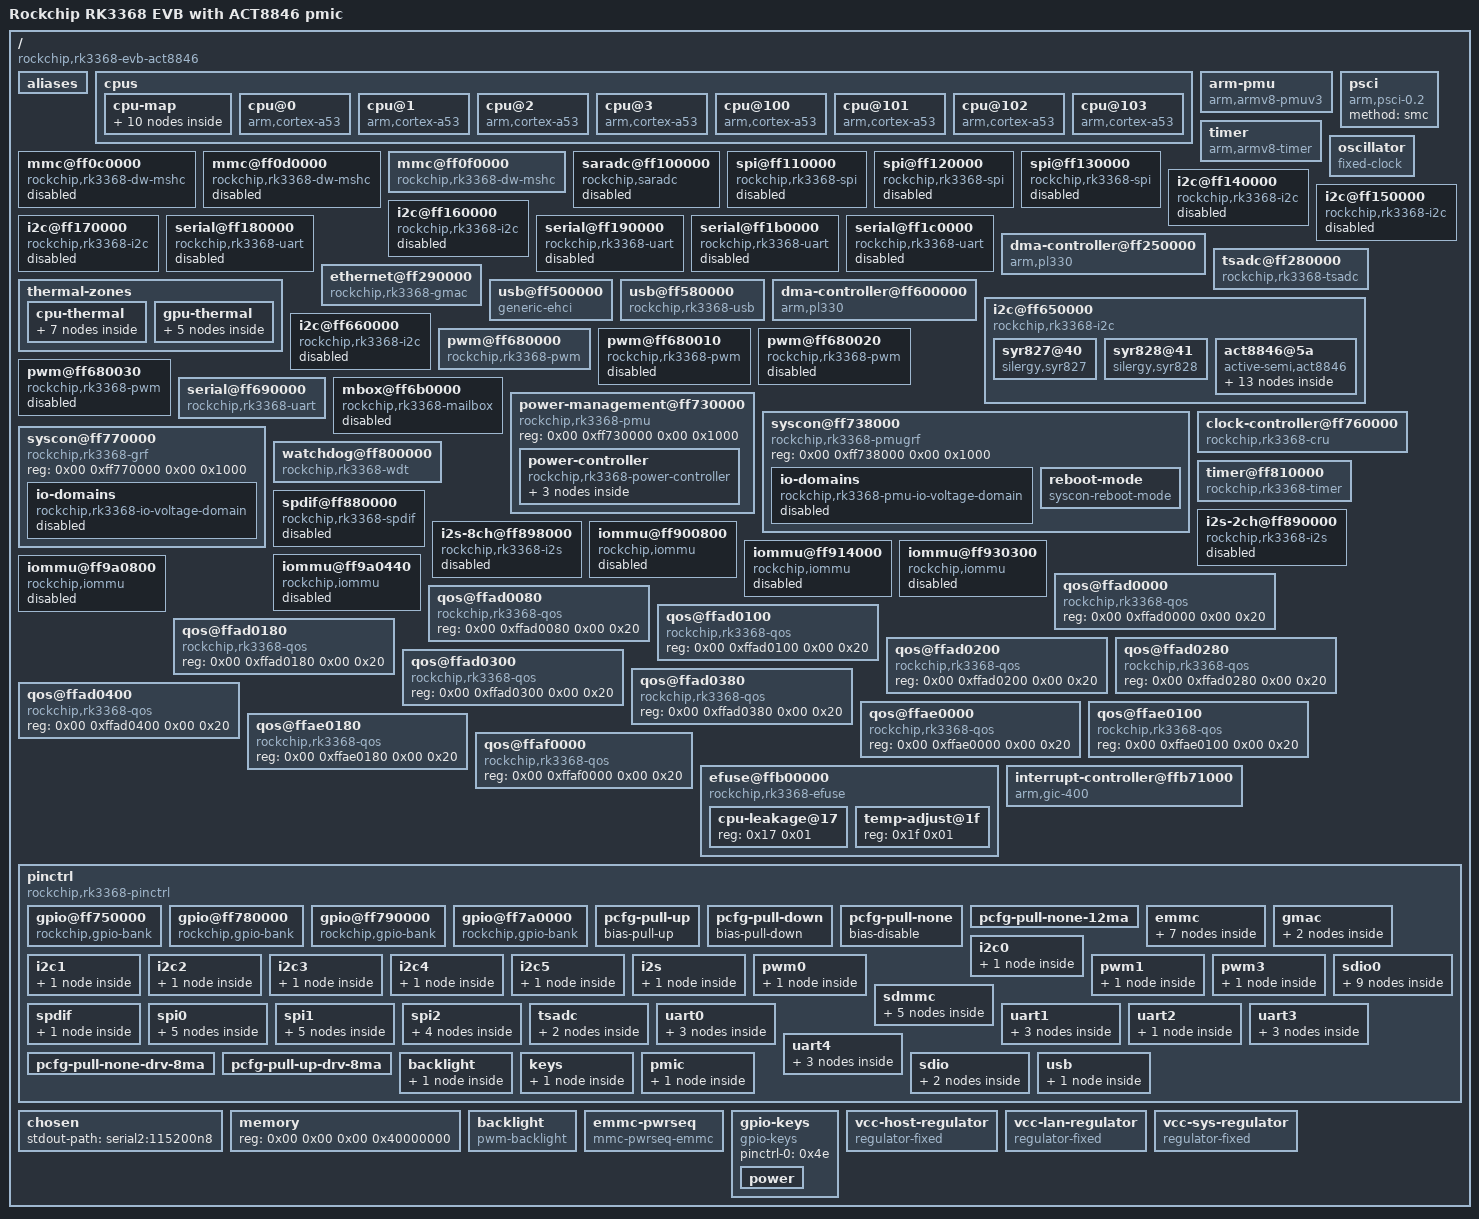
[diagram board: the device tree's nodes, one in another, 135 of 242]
/dts-v1/;

/ {
	compatible = "rockchip,rk3368-evb-act8846\0rockchip,rk3368";
	interrupt-parent = <0x01>;
	#address-cells = <0x02>;
	#size-cells = <0x02>;
	model = "Rockchip RK3368 EVB with ACT8846 pmic";

	aliases {
		ethernet0 = "/ethernet@ff290000";
		i2c0 = "/i2c@ff650000";
		i2c1 = "/i2c@ff660000";
		i2c2 = "/i2c@ff140000";
		i2c3 = "/i2c@ff150000";
		i2c4 = "/i2c@ff160000";
		i2c5 = "/i2c@ff170000";
		serial0 = "/serial@ff180000";
		serial1 = "/serial@ff190000";
		serial2 = "/serial@ff690000";
		serial3 = "/serial@ff1b0000";
		serial4 = "/serial@ff1c0000";
		spi0 = "/spi@ff110000";
		spi1 = "/spi@ff120000";
		spi2 = "/spi@ff130000";
		mmc0 = "/mmc@ff0f0000";
	};

	cpus {
		#address-cells = <0x02>;
		#size-cells = <0x00>;

		cpu-map {

			cluster0 {

				core0 {
					cpu = <0x02>;
				};

				core1 {
					cpu = <0x03>;
				};

				core2 {
					cpu = <0x04>;
				};

				core3 {
					cpu = <0x05>;
				};
			};

			cluster1 {

				core0 {
					cpu = <0x06>;
				};

				core1 {
					cpu = <0x07>;
				};

				core2 {
					cpu = <0x08>;
				};

				core3 {
					cpu = <0x09>;
				};
			};
		};

		cpu@0 {
			device_type = "cpu";
			compatible = "arm,cortex-a53";
			reg = <0x00 0x00>;
			enable-method = "psci";
			#cooling-cells = <0x02>;
			phandle = <0x06>;
		};

		cpu@1 {
			device_type = "cpu";
			compatible = "arm,cortex-a53";
			reg = <0x00 0x01>;
			enable-method = "psci";
			#cooling-cells = <0x02>;
			phandle = <0x07>;
		};

		cpu@2 {
			device_type = "cpu";
			compatible = "arm,cortex-a53";
			reg = <0x00 0x02>;
			enable-method = "psci";
			#cooling-cells = <0x02>;
			phandle = <0x08>;
		};

		cpu@3 {
			device_type = "cpu";
			compatible = "arm,cortex-a53";
			reg = <0x00 0x03>;
			enable-method = "psci";
			#cooling-cells = <0x02>;
			phandle = <0x09>;
		};

		cpu@100 {
			device_type = "cpu";
			compatible = "arm,cortex-a53";
			reg = <0x00 0x100>;
			enable-method = "psci";
			#cooling-cells = <0x02>;
			phandle = <0x02>;
		};

		cpu@101 {
			device_type = "cpu";
			compatible = "arm,cortex-a53";
			reg = <0x00 0x101>;
			enable-method = "psci";
			#cooling-cells = <0x02>;
			phandle = <0x03>;
		};

		cpu@102 {
			device_type = "cpu";
			compatible = "arm,cortex-a53";
			reg = <0x00 0x102>;
			enable-method = "psci";
			#cooling-cells = <0x02>;
			phandle = <0x04>;
		};

		cpu@103 {
			device_type = "cpu";
			compatible = "arm,cortex-a53";
			reg = <0x00 0x103>;
			enable-method = "psci";
			#cooling-cells = <0x02>;
			phandle = <0x05>;
		};
	};

	arm-pmu {
		compatible = "arm,armv8-pmuv3";
		interrupts = <0x00 0x70 0x04 0x00 0x71 0x04 0x00 0x72 0x04 0x00 0x73 0x04 0x00 0x74 0x04 0x00 0x75 0x04 0x00 0x76 0x04 0x00 0x77 0x04>;
		interrupt-affinity = <0x06 0x07 0x08 0x09 0x02 0x03 0x04 0x05>;
	};

	psci {
		compatible = "arm,psci-0.2";
		method = "smc";
	};

	timer {
		compatible = "arm,armv8-timer";
		interrupts = <0x01 0x0d 0xff04 0x01 0x0e 0xff04 0x01 0x0b 0xff04 0x01 0x0a 0xff04>;
	};

	oscillator {
		compatible = "fixed-clock";
		clock-frequency = <0x16e3600>;
		clock-output-names = "xin24m";
		#clock-cells = <0x00>;
		phandle = <0x50>;
	};

	mmc@ff0c0000 {
		compatible = "rockchip,rk3368-dw-mshc\0rockchip,rk3288-dw-mshc";
		reg = <0x00 0xff0c0000 0x00 0x4000>;
		max-frequency = <0x8f0d180>;
		clocks = <0x0a 0x1c8 0x0a 0x44 0x0a 0x72 0x0a 0x76>;
		clock-names = "biu\0ciu\0ciu-drive\0ciu-sample";
		fifo-depth = <0x100>;
		interrupts = <0x00 0x20 0x04>;
		resets = <0x0a 0x80>;
		reset-names = "reset";
		status = "disabled";
		phandle = <0x51>;
	};

	mmc@ff0d0000 {
		compatible = "rockchip,rk3368-dw-mshc\0rockchip,rk3288-dw-mshc";
		reg = <0x00 0xff0d0000 0x00 0x4000>;
		max-frequency = <0x8f0d180>;
		clocks = <0x0a 0x1c9 0x0a 0x45 0x0a 0x73 0x0a 0x77>;
		clock-names = "biu\0ciu\0ciu-drive\0ciu-sample";
		fifo-depth = <0x100>;
		interrupts = <0x00 0x21 0x04>;
		resets = <0x0a 0x81>;
		reset-names = "reset";
		status = "disabled";
		phandle = <0x52>;
	};

	mmc@ff0f0000 {
		compatible = "rockchip,rk3368-dw-mshc\0rockchip,rk3288-dw-mshc";
		reg = <0x00 0xff0f0000 0x00 0x4000>;
		max-frequency = <0x8f0d180>;
		clocks = <0x0a 0x1cb 0x0a 0x47 0x0a 0x75 0x0a 0x79>;
		clock-names = "biu\0ciu\0ciu-drive\0ciu-sample";
		fifo-depth = <0x100>;
		interrupts = <0x00 0x23 0x04>;
		resets = <0x0a 0x83>;
		reset-names = "reset";
		status = "okay";
		bus-width = <0x08>;
		cap-mmc-highspeed;
		mmc-pwrseq = <0x0b>;
		non-removable;
		pinctrl-names = "default";
		pinctrl-0 = <0x0c 0x0d 0x0e>;
		phandle = <0x53>;
	};

	saradc@ff100000 {
		compatible = "rockchip,saradc";
		reg = <0x00 0xff100000 0x00 0x100>;
		interrupts = <0x00 0x24 0x04>;
		#io-channel-cells = <0x01>;
		clocks = <0x0a 0x49 0x0a 0x15b>;
		clock-names = "saradc\0apb_pclk";
		resets = <0x0a 0x57>;
		reset-names = "saradc-apb";
		status = "disabled";
		phandle = <0x54>;
	};

	spi@ff110000 {
		compatible = "rockchip,rk3368-spi\0rockchip,rk3066-spi";
		reg = <0x00 0xff110000 0x00 0x1000>;
		clocks = <0x0a 0x41 0x0a 0x152>;
		clock-names = "spiclk\0apb_pclk";
		interrupts = <0x00 0x2c 0x04>;
		pinctrl-names = "default";
		pinctrl-0 = <0x0f 0x10 0x11 0x12>;
		#address-cells = <0x01>;
		#size-cells = <0x00>;
		status = "disabled";
		phandle = <0x55>;
	};

	spi@ff120000 {
		compatible = "rockchip,rk3368-spi\0rockchip,rk3066-spi";
		reg = <0x00 0xff120000 0x00 0x1000>;
		clocks = <0x0a 0x42 0x0a 0x153>;
		clock-names = "spiclk\0apb_pclk";
		interrupts = <0x00 0x2d 0x04>;
		pinctrl-names = "default";
		pinctrl-0 = <0x13 0x14 0x15 0x16>;
		#address-cells = <0x01>;
		#size-cells = <0x00>;
		status = "disabled";
		phandle = <0x56>;
	};

	spi@ff130000 {
		compatible = "rockchip,rk3368-spi\0rockchip,rk3066-spi";
		reg = <0x00 0xff130000 0x00 0x1000>;
		clocks = <0x0a 0x43 0x0a 0x154>;
		clock-names = "spiclk\0apb_pclk";
		interrupts = <0x00 0x29 0x04>;
		pinctrl-names = "default";
		pinctrl-0 = <0x17 0x18 0x19 0x1a>;
		#address-cells = <0x01>;
		#size-cells = <0x00>;
		status = "disabled";
		phandle = <0x57>;
	};

	i2c@ff140000 {
		compatible = "rockchip,rk3368-i2c\0rockchip,rk3288-i2c";
		reg = <0x00 0xff140000 0x00 0x1000>;
		interrupts = <0x00 0x3e 0x04>;
		#address-cells = <0x01>;
		#size-cells = <0x00>;
		clock-names = "i2c";
		clocks = <0x0a 0x14e>;
		pinctrl-names = "default";
		pinctrl-0 = <0x1b>;
		status = "disabled";
		phandle = <0x58>;
	};

	i2c@ff150000 {
		compatible = "rockchip,rk3368-i2c\0rockchip,rk3288-i2c";
		reg = <0x00 0xff150000 0x00 0x1000>;
		interrupts = <0x00 0x3f 0x04>;
		#address-cells = <0x01>;
		#size-cells = <0x00>;
		clock-names = "i2c";
		clocks = <0x0a 0x14f>;
		pinctrl-names = "default";
		pinctrl-0 = <0x1c>;
		status = "disabled";
		phandle = <0x59>;
	};

	i2c@ff160000 {
		compatible = "rockchip,rk3368-i2c\0rockchip,rk3288-i2c";
		reg = <0x00 0xff160000 0x00 0x1000>;
		interrupts = <0x00 0x40 0x04>;
		#address-cells = <0x01>;
		#size-cells = <0x00>;
		clock-names = "i2c";
		clocks = <0x0a 0x150>;
		pinctrl-names = "default";
		pinctrl-0 = <0x1d>;
		status = "disabled";
		phandle = <0x5a>;
	};

	i2c@ff170000 {
		compatible = "rockchip,rk3368-i2c\0rockchip,rk3288-i2c";
		reg = <0x00 0xff170000 0x00 0x1000>;
		interrupts = <0x00 0x41 0x04>;
		#address-cells = <0x01>;
		#size-cells = <0x00>;
		clock-names = "i2c";
		clocks = <0x0a 0x151>;
		pinctrl-names = "default";
		pinctrl-0 = <0x1e>;
		status = "disabled";
		phandle = <0x5b>;
	};

	serial@ff180000 {
		compatible = "rockchip,rk3368-uart\0snps,dw-apb-uart";
		reg = <0x00 0xff180000 0x00 0x100>;
		clock-frequency = <0x16e3600>;
		clocks = <0x0a 0x4d 0x0a 0x155>;
		clock-names = "baudclk\0apb_pclk";
		interrupts = <0x00 0x37 0x04>;
		reg-shift = <0x02>;
		reg-io-width = <0x04>;
		status = "disabled";
		phandle = <0x5c>;
	};

	serial@ff190000 {
		compatible = "rockchip,rk3368-uart\0snps,dw-apb-uart";
		reg = <0x00 0xff190000 0x00 0x100>;
		clock-frequency = <0x16e3600>;
		clocks = <0x0a 0x4e 0x0a 0x156>;
		clock-names = "baudclk\0apb_pclk";
		interrupts = <0x00 0x38 0x04>;
		reg-shift = <0x02>;
		reg-io-width = <0x04>;
		status = "disabled";
		phandle = <0x5d>;
	};

	serial@ff1b0000 {
		compatible = "rockchip,rk3368-uart\0snps,dw-apb-uart";
		reg = <0x00 0xff1b0000 0x00 0x100>;
		clock-frequency = <0x16e3600>;
		clocks = <0x0a 0x50 0x0a 0x158>;
		clock-names = "baudclk\0apb_pclk";
		interrupts = <0x00 0x3a 0x04>;
		reg-shift = <0x02>;
		reg-io-width = <0x04>;
		status = "disabled";
		phandle = <0x5e>;
	};

	serial@ff1c0000 {
		compatible = "rockchip,rk3368-uart\0snps,dw-apb-uart";
		reg = <0x00 0xff1c0000 0x00 0x100>;
		clock-frequency = <0x16e3600>;
		clocks = <0x0a 0x51 0x0a 0x159>;
		clock-names = "baudclk\0apb_pclk";
		interrupts = <0x00 0x3b 0x04>;
		reg-shift = <0x02>;
		reg-io-width = <0x04>;
		status = "disabled";
		phandle = <0x5f>;
	};

	dma-controller@ff250000 {
		compatible = "arm,pl330\0arm,primecell";
		reg = <0x00 0xff250000 0x00 0x4000>;
		interrupts = <0x00 0x02 0x04 0x00 0x03 0x04>;
		#dma-cells = <0x01>;
		arm,pl330-broken-no-flushp;
		arm,pl330-periph-burst;
		clocks = <0x0a 0xc3>;
		clock-names = "apb_pclk";
		phandle = <0x60>;
	};

	thermal-zones {

		cpu-thermal {
			polling-delay-passive = <0x64>;
			polling-delay = <0x1388>;
			thermal-sensors = <0x1f 0x00>;
			phandle = <0x61>;

			trips {

				cpu_alert0 {
					temperature = <0x124f8>;
					hysteresis = <0x7d0>;
					type = "passive";
					phandle = <0x20>;
				};

				cpu_alert1 {
					temperature = <0x13880>;
					hysteresis = <0x7d0>;
					type = "passive";
					phandle = <0x21>;
				};

				cpu_crit {
					temperature = <0x17318>;
					hysteresis = <0x7d0>;
					type = "critical";
					phandle = <0x62>;
				};
			};

			cooling-maps {

				map0 {
					trip = <0x20>;
					cooling-device = <0x02 0xffffffff 0xffffffff 0x03 0xffffffff 0xffffffff 0x04 0xffffffff 0xffffffff 0x05 0xffffffff 0xffffffff>;
				};

				map1 {
					trip = <0x21>;
					cooling-device = <0x06 0xffffffff 0xffffffff 0x07 0xffffffff 0xffffffff 0x08 0xffffffff 0xffffffff 0x09 0xffffffff 0xffffffff>;
				};
			};
		};

		gpu-thermal {
			polling-delay-passive = <0x64>;
			polling-delay = <0x1388>;
			thermal-sensors = <0x1f 0x01>;
			phandle = <0x63>;

			trips {

				gpu_alert0 {
					temperature = <0x13880>;
					hysteresis = <0x7d0>;
					type = "passive";
					phandle = <0x22>;
				};

				gpu_crit {
					temperature = <0x1c138>;
					hysteresis = <0x7d0>;
					type = "critical";
					phandle = <0x64>;
				};
			};

			cooling-maps {

				map0 {
					trip = <0x22>;
					cooling-device = <0x02 0xffffffff 0xffffffff 0x03 0xffffffff 0xffffffff 0x04 0xffffffff 0xffffffff 0x05 0xffffffff 0xffffffff>;
				};
			};
		};
	};

	tsadc@ff280000 {
		compatible = "rockchip,rk3368-tsadc";
		reg = <0x00 0xff280000 0x00 0x100>;
		interrupts = <0x00 0x25 0x04>;
		clocks = <0x0a 0x48 0x0a 0x15a>;
		clock-names = "tsadc\0apb_pclk";
		resets = <0x0a 0x9f>;
		reset-names = "tsadc-apb";
		pinctrl-names = "init\0default\0sleep";
		pinctrl-0 = <0x23>;
		pinctrl-1 = <0x24>;
		pinctrl-2 = <0x23>;
		#thermal-sensor-cells = <0x01>;
		rockchip,hw-tshut-temp = <0x17318>;
		status = "okay";
		rockchip,hw-tshut-mode = <0x00>;
		rockchip,hw-tshut-polarity = <0x00>;
		phandle = <0x1f>;
	};

	ethernet@ff290000 {
		compatible = "rockchip,rk3368-gmac";
		reg = <0x00 0xff290000 0x00 0x10000>;
		interrupts = <0x00 0x1b 0x04>;
		interrupt-names = "macirq";
		rockchip,grf = <0x25>;
		clocks = <0x0a 0x7f 0x0a 0x66 0x0a 0x67 0x0a 0x63 0x0a 0x80 0x0a 0xc5 0x0a 0x15d>;
		clock-names = "stmmaceth\0mac_clk_rx\0mac_clk_tx\0clk_mac_ref\0clk_mac_refout\0aclk_mac\0pclk_mac";
		status = "okay";
		phy-supply = <0x26>;
		phy-mode = "rmii";
		clock_in_out = "output";
		snps,reset-gpio = <0x27 0x0c 0x00>;
		snps,reset-active-low;
		snps,reset-delays-us = <0x00 0x2710 0xf4240>;
		pinctrl-names = "default";
		pinctrl-0 = <0x28>;
		tx_delay = <0x30>;
		rx_delay = <0x10>;
		phandle = <0x65>;
	};

	usb@ff500000 {
		compatible = "generic-ehci";
		reg = <0x00 0xff500000 0x00 0x100>;
		interrupts = <0x00 0x18 0x04>;
		clocks = <0x0a 0x1c2>;
		status = "okay";
		phandle = <0x66>;
	};

	usb@ff580000 {
		compatible = "rockchip,rk3368-usb\0rockchip,rk3066-usb\0snps,dwc2";
		reg = <0x00 0xff580000 0x00 0x40000>;
		interrupts = <0x00 0x17 0x04>;
		clocks = <0x0a 0x1c1>;
		clock-names = "otg";
		dr_mode = "host";
		g-np-tx-fifo-size = <0x10>;
		g-rx-fifo-size = <0x113>;
		g-tx-fifo-size = <0x100 0x80 0x80 0x40 0x40 0x20>;
		status = "okay";
		phandle = <0x67>;
	};

	dma-controller@ff600000 {
		compatible = "arm,pl330\0arm,primecell";
		reg = <0x00 0xff600000 0x00 0x4000>;
		interrupts = <0x00 0x00 0x04 0x00 0x01 0x04>;
		#dma-cells = <0x01>;
		arm,pl330-broken-no-flushp;
		arm,pl330-periph-burst;
		clocks = <0x0a 0xc2>;
		clock-names = "apb_pclk";
		phandle = <0x3f>;
	};

	i2c@ff650000 {
		compatible = "rockchip,rk3368-i2c\0rockchip,rk3288-i2c";
		reg = <0x00 0xff650000 0x00 0x1000>;
		clocks = <0x0a 0x14c>;
		clock-names = "i2c";
		interrupts = <0x00 0x3c 0x04>;
		pinctrl-names = "default";
		pinctrl-0 = <0x29>;
		#address-cells = <0x01>;
		#size-cells = <0x00>;
		status = "okay";
		clock-frequency = <0x61a80>;
		phandle = <0x68>;

		syr827@40 {
			compatible = "silergy,syr827";
			reg = <0x40>;
			fcs,suspend-voltage-selector = <0x01>;
			regulator-name = "vdd_cpu";
			regulator-min-microvolt = <0xcf850>;
			regulator-max-microvolt = <0x149970>;
			regulator-always-on;
			regulator-boot-on;
			vin-supply = <0x2a>;
			phandle = <0x69>;
		};

		syr828@41 {
			compatible = "silergy,syr828";
			reg = <0x41>;
			fcs,suspend-voltage-selector = <0x01>;
			regulator-name = "vdd_gpu";
			regulator-min-microvolt = <0xcf850>;
			regulator-max-microvolt = <0x149970>;
			regulator-always-on;
			vin-supply = <0x2a>;
			phandle = <0x6a>;
		};

		act8846@5a {
			compatible = "active-semi,act8846";
			reg = <0x5a>;
			status = "okay";
			vp1-supply = <0x2a>;
			vp2-supply = <0x2a>;
			vp3-supply = <0x2a>;
			vp4-supply = <0x2a>;
			inl1-supply = <0x2b>;
			inl2-supply = <0x2a>;
			inl3-supply = <0x2c>;
			phandle = <0x6b>;

			regulators {

				REG1 {
					regulator-name = "VCC_DDR";
					regulator-min-microvolt = <0x124f80>;
					regulator-max-microvolt = <0x124f80>;
					regulator-always-on;
					phandle = <0x6c>;
				};

				REG2 {
					regulator-name = "VCC_IO";
					regulator-min-microvolt = <0x325aa0>;
					regulator-max-microvolt = <0x325aa0>;
					regulator-always-on;
					phandle = <0x2b>;
				};

				REG3 {
					regulator-name = "VDD_LOG";
					regulator-min-microvolt = <0xaae60>;
					regulator-max-microvolt = <0x16e360>;
					regulator-always-on;
					phandle = <0x6d>;
				};

				REG4 {
					regulator-name = "VCC_20";
					regulator-min-microvolt = <0x1e8480>;
					regulator-max-microvolt = <0x1e8480>;
					regulator-always-on;
					phandle = <0x2c>;
				};

				REG5 {
					regulator-name = "VCCIO_SD";
					regulator-min-microvolt = <0x1b7740>;
					regulator-max-microvolt = <0x325aa0>;
					regulator-always-on;
					phandle = <0x6e>;
				};

				REG6 {
					regulator-name = "VDD10_LCD";
					regulator-min-microvolt = <0xf4240>;
					regulator-max-microvolt = <0xf4240>;
					regulator-always-on;
					phandle = <0x6f>;
				};

				REG7 {
					regulator-name = "VCCA_CODEC";
					regulator-min-microvolt = <0x325aa0>;
					regulator-max-microvolt = <0x325aa0>;
					regulator-always-on;
					phandle = <0x70>;
				};

				REG8 {
					regulator-name = "VCCA_TP";
					regulator-min-microvolt = <0x325aa0>;
					regulator-max-microvolt = <0x325aa0>;
					regulator-always-on;
					phandle = <0x71>;
				};

				REG9 {
					regulator-name = "VCCIO_PMU";
					regulator-min-microvolt = <0x325aa0>;
					regulator-max-microvolt = <0x325aa0>;
					regulator-always-on;
					phandle = <0x72>;
				};

				REG10 {
					regulator-name = "VDD_10";
					regulator-min-microvolt = <0xf4240>;
					regulator-max-microvolt = <0xf4240>;
					regulator-always-on;
					phandle = <0x73>;
				};

				REG11 {
					regulator-name = "VCC_18";
					regulator-min-microvolt = <0x1b7740>;
					regulator-max-microvolt = <0x1b7740>;
					regulator-always-on;
					phandle = <0x74>;
				};

				REG12 {
					regulator-name = "VCC18_LCD";
					regulator-min-microvolt = <0x1b7740>;
					regulator-max-microvolt = <0x1b7740>;
					regulator-always-on;
					phandle = <0x75>;
				};
			};
		};
	};

	i2c@ff660000 {
		compatible = "rockchip,rk3368-i2c\0rockchip,rk3288-i2c";
		reg = <0x00 0xff660000 0x00 0x1000>;
		interrupts = <0x00 0x3d 0x04>;
		#address-cells = <0x01>;
		#size-cells = <0x00>;
		clock-names = "i2c";
		clocks = <0x0a 0x14d>;
		pinctrl-names = "default";
		pinctrl-0 = <0x2d>;
		status = "disabled";
		phandle = <0x76>;
	};

	pwm@ff680000 {
		compatible = "rockchip,rk3368-pwm\0rockchip,rk3288-pwm";
		reg = <0x00 0xff680000 0x00 0x10>;
		#pwm-cells = <0x03>;
		pinctrl-names = "default";
		pinctrl-0 = <0x2e>;
		clocks = <0x0a 0x15f>;
		status = "okay";
		phandle = <0x4b>;
	};

	pwm@ff680010 {
		compatible = "rockchip,rk3368-pwm\0rockchip,rk3288-pwm";
		reg = <0x00 0xff680010 0x00 0x10>;
		#pwm-cells = <0x03>;
		pinctrl-names = "default";
		pinctrl-0 = <0x2f>;
		clocks = <0x0a 0x15f>;
		status = "disabled";
		phandle = <0x77>;
	};

	pwm@ff680020 {
		compatible = "rockchip,rk3368-pwm\0rockchip,rk3288-pwm";
		reg = <0x00 0xff680020 0x00 0x10>;
		#pwm-cells = <0x03>;
		clocks = <0x0a 0x15f>;
		status = "disabled";
		phandle = <0x78>;
	};

	pwm@ff680030 {
		compatible = "rockchip,rk3368-pwm\0rockchip,rk3288-pwm";
		reg = <0x00 0xff680030 0x00 0x10>;
		#pwm-cells = <0x03>;
		pinctrl-names = "default";
		pinctrl-0 = <0x30>;
		clocks = <0x0a 0x15f>;
		status = "disabled";
		phandle = <0x79>;
	};

	serial@ff690000 {
		compatible = "rockchip,rk3368-uart\0snps,dw-apb-uart";
		reg = <0x00 0xff690000 0x00 0x100>;
		clocks = <0x0a 0x4f 0x0a 0x157>;
		clock-names = "baudclk\0apb_pclk";
		interrupts = <0x00 0x39 0x04>;
		pinctrl-names = "default";
		pinctrl-0 = <0x31>;
		reg-shift = <0x02>;
		reg-io-width = <0x04>;
		status = "okay";
		phandle = <0x7a>;
	};

	mbox@ff6b0000 {
		compatible = "rockchip,rk3368-mailbox";
		reg = <0x00 0xff6b0000 0x00 0x1000>;
		interrupts = <0x00 0x92 0x04 0x00 0x93 0x04 0x00 0x94 0x04 0x00 0x95 0x04>;
		clocks = <0x0a 0x145>;
		clock-names = "pclk_mailbox";
		#mbox-cells = <0x01>;
		status = "disabled";
		phandle = <0x7b>;
	};

	power-management@ff730000 {
		compatible = "rockchip,rk3368-pmu\0syscon\0simple-mfd";
		reg = <0x00 0xff730000 0x00 0x1000>;
		phandle = <0x7c>;

		power-controller {
			compatible = "rockchip,rk3368-power-controller";
			#power-domain-cells = <0x01>;
			#address-cells = <0x01>;
			#size-cells = <0x00>;
			phandle = <0x42>;

			power-domain@12 {
				reg = <0x0c>;
				clocks = <0x0a 0xca 0x0a 0xcd 0x0a 0xcc 0x0a 0xc8 0x0a 0xc6 0x0a 0xc7 0x0a 0xbe 0x0a 0x1d4 0x0a 0x1d5 0x0a 0x1d6 0x0a 0x1d9 0x0a 0x1d1 0x0a 0x1db 0x0a 0x163 0x0a 0x168 0x0a 0x167 0x0a 0x16e 0x0a 0x16f 0x0a 0x172 0x0a 0x173 0x0a 0x166 0x0a 0x164 0x0a 0x64 0x0a 0x68 0x0a 0x69 0x0a 0x6c 0x0a 0x6b 0x0a 0x6a 0x0a 0x6e 0x0a 0x6d>;
				pm_qos = <0x32 0x33 0x34 0x35 0x36 0x37 0x38 0x39 0x3a>;
				#power-domain-cells = <0x00>;
			};

			power-domain@14 {
				reg = <0x0e>;
				clocks = <0x0a 0xd0 0x0a 0x1dc 0x0a 0x6f 0x0a 0x70>;
				pm_qos = <0x3b 0x3c 0x3d>;
				#power-domain-cells = <0x00>;
			};

			power-domain@16 {
				reg = <0x10>;
				clocks = <0x0a 0xc1 0x0a 0xc0 0x0a 0x40>;
				pm_qos = <0x3e>;
				#power-domain-cells = <0x00>;
			};
		};
	};

	syscon@ff738000 {
		compatible = "rockchip,rk3368-pmugrf\0syscon\0simple-mfd";
		reg = <0x00 0xff738000 0x00 0x1000>;
		phandle = <0x43>;

		io-domains {
			compatible = "rockchip,rk3368-pmu-io-voltage-domain";
			status = "disabled";
			phandle = <0x7d>;
		};

		reboot-mode {
			compatible = "syscon-reboot-mode";
			offset = <0x200>;
			mode-normal = <0x5242c300>;
			mode-recovery = <0x5242c303>;
			mode-bootloader = <0x5242c309>;
			mode-loader = <0x5242c301>;
		};
	};

	clock-controller@ff760000 {
		compatible = "rockchip,rk3368-cru";
		reg = <0x00 0xff760000 0x00 0x1000>;
		rockchip,grf = <0x25>;
		#clock-cells = <0x01>;
		#reset-cells = <0x01>;
		phandle = <0x0a>;
	};

	syscon@ff770000 {
		compatible = "rockchip,rk3368-grf\0syscon\0simple-mfd";
		reg = <0x00 0xff770000 0x00 0x1000>;
		phandle = <0x25>;

		io-domains {
			compatible = "rockchip,rk3368-io-voltage-domain";
			status = "disabled";
			phandle = <0x7e>;
		};
	};

	watchdog@ff800000 {
		compatible = "rockchip,rk3368-wdt\0snps,dw-wdt";
		reg = <0x00 0xff800000 0x00 0x100>;
		clocks = <0x0a 0x170>;
		interrupts = <0x00 0x4f 0x04>;
		status = "okay";
		phandle = <0x7f>;
	};

	timer@ff810000 {
		compatible = "rockchip,rk3368-timer\0rockchip,rk3288-timer";
		reg = <0x00 0xff810000 0x00 0x20>;
		interrupts = <0x00 0x42 0x04>;
		clocks = <0x0a 0x161 0x0a 0x55>;
		clock-names = "pclk\0timer";
		phandle = <0x80>;
	};

	spdif@ff880000 {
		compatible = "rockchip,rk3368-spdif";
		reg = <0x00 0xff880000 0x00 0x1000>;
		interrupts = <0x00 0x36 0x04>;
		clocks = <0x0a 0x53 0x0a 0x1d0>;
		clock-names = "mclk\0hclk";
		dmas = <0x3f 0x03>;
		dma-names = "tx";
		pinctrl-names = "default";
		pinctrl-0 = <0x40>;
		status = "disabled";
		phandle = <0x81>;
	};

	i2s-2ch@ff890000 {
		compatible = "rockchip,rk3368-i2s\0rockchip,rk3066-i2s";
		reg = <0x00 0xff890000 0x00 0x1000>;
		interrupts = <0x00 0x28 0x04>;
		clock-names = "i2s_clk\0i2s_hclk";
		clocks = <0x0a 0x54 0x0a 0x1ce>;
		dmas = <0x3f 0x06 0x3f 0x07>;
		dma-names = "tx\0rx";
		status = "disabled";
		phandle = <0x82>;
	};

	i2s-8ch@ff898000 {
		compatible = "rockchip,rk3368-i2s\0rockchip,rk3066-i2s";
		reg = <0x00 0xff898000 0x00 0x1000>;
		interrupts = <0x00 0x35 0x04>;
		clock-names = "i2s_clk\0i2s_hclk";
		clocks = <0x0a 0x52 0x0a 0x1cf>;
		dmas = <0x3f 0x00 0x3f 0x01>;
		dma-names = "tx\0rx";
		pinctrl-names = "default";
		pinctrl-0 = <0x41>;
		status = "disabled";
		phandle = <0x83>;
	};

	iommu@ff900800 {
		compatible = "rockchip,iommu";
		reg = <0x00 0xff900800 0x00 0x100>;
		interrupts = <0x00 0x11 0x04>;
		clocks = <0x0a 0xca 0x0a 0x1d4>;
		clock-names = "aclk\0iface";
		power-domains = <0x42 0x0c>;
		#iommu-cells = <0x00>;
		status = "disabled";
		phandle = <0x84>;
	};

	iommu@ff914000 {
		compatible = "rockchip,iommu";
		reg = <0x00 0xff914000 0x00 0x100 0x00 0xff915000 0x00 0x100>;
		interrupts = <0x00 0x0e 0x04>;
		clocks = <0x0a 0xcd 0x0a 0x1d5>;
		clock-names = "aclk\0iface";
		#iommu-cells = <0x00>;
		power-domains = <0x42 0x0c>;
		rockchip,disable-mmu-reset;
		status = "disabled";
		phandle = <0x85>;
	};

	iommu@ff930300 {
		compatible = "rockchip,iommu";
		reg = <0x00 0xff930300 0x00 0x100>;
		interrupts = <0x00 0x0f 0x04>;
		clocks = <0x0a 0xc6 0x0a 0x1d1>;
		clock-names = "aclk\0iface";
		power-domains = <0x42 0x0c>;
		#iommu-cells = <0x00>;
		status = "disabled";
		phandle = <0x86>;
	};

	iommu@ff9a0440 {
		compatible = "rockchip,iommu";
		reg = <0x00 0xff9a0440 0x00 0x40 0x00 0xff9a0480 0x00 0x40>;
		interrupts = <0x00 0x0c 0x04>;
		clocks = <0x0a 0xd0 0x0a 0x1dc>;
		clock-names = "aclk\0iface";
		#iommu-cells = <0x00>;
		status = "disabled";
		phandle = <0x87>;
	};

	iommu@ff9a0800 {
		compatible = "rockchip,iommu";
		reg = <0x00 0xff9a0800 0x00 0x100>;
		interrupts = <0x00 0x09 0x04 0x00 0x0a 0x04>;
		clocks = <0x0a 0xd0 0x0a 0x1dc>;
		clock-names = "aclk\0iface";
		#iommu-cells = <0x00>;
		status = "disabled";
		phandle = <0x88>;
	};

	qos@ffad0000 {
		compatible = "rockchip,rk3368-qos\0syscon";
		reg = <0x00 0xffad0000 0x00 0x20>;
		phandle = <0x32>;
	};

	qos@ffad0080 {
		compatible = "rockchip,rk3368-qos\0syscon";
		reg = <0x00 0xffad0080 0x00 0x20>;
		phandle = <0x33>;
	};

	qos@ffad0100 {
		compatible = "rockchip,rk3368-qos\0syscon";
		reg = <0x00 0xffad0100 0x00 0x20>;
		phandle = <0x34>;
	};

	qos@ffad0180 {
		compatible = "rockchip,rk3368-qos\0syscon";
		reg = <0x00 0xffad0180 0x00 0x20>;
		phandle = <0x35>;
	};

	qos@ffad0200 {
		compatible = "rockchip,rk3368-qos\0syscon";
		reg = <0x00 0xffad0200 0x00 0x20>;
		phandle = <0x36>;
	};

	qos@ffad0280 {
		compatible = "rockchip,rk3368-qos\0syscon";
		reg = <0x00 0xffad0280 0x00 0x20>;
		phandle = <0x37>;
	};

	qos@ffad0300 {
		compatible = "rockchip,rk3368-qos\0syscon";
		reg = <0x00 0xffad0300 0x00 0x20>;
		phandle = <0x38>;
	};

	qos@ffad0380 {
		compatible = "rockchip,rk3368-qos\0syscon";
		reg = <0x00 0xffad0380 0x00 0x20>;
		phandle = <0x39>;
	};

	qos@ffad0400 {
		compatible = "rockchip,rk3368-qos\0syscon";
		reg = <0x00 0xffad0400 0x00 0x20>;
		phandle = <0x3a>;
	};

	qos@ffae0000 {
		compatible = "rockchip,rk3368-qos\0syscon";
		reg = <0x00 0xffae0000 0x00 0x20>;
		phandle = <0x3b>;
	};

	qos@ffae0100 {
		compatible = "rockchip,rk3368-qos\0syscon";
		reg = <0x00 0xffae0100 0x00 0x20>;
		phandle = <0x3c>;
	};

	qos@ffae0180 {
		compatible = "rockchip,rk3368-qos\0syscon";
		reg = <0x00 0xffae0180 0x00 0x20>;
		phandle = <0x3d>;
	};

	qos@ffaf0000 {
		compatible = "rockchip,rk3368-qos\0syscon";
		reg = <0x00 0xffaf0000 0x00 0x20>;
		phandle = <0x3e>;
	};

	efuse@ffb00000 {
		compatible = "rockchip,rk3368-efuse";
		reg = <0x00 0xffb00000 0x00 0x20>;
		#address-cells = <0x01>;
		#size-cells = <0x01>;
		clocks = <0x0a 0x171>;
		clock-names = "pclk_efuse";
		phandle = <0x89>;

		cpu-leakage@17 {
			reg = <0x17 0x01>;
			phandle = <0x8a>;
		};

		temp-adjust@1f {
			reg = <0x1f 0x01>;
			phandle = <0x8b>;
		};
	};

	interrupt-controller@ffb71000 {
		compatible = "arm,gic-400";
		interrupt-controller;
		#interrupt-cells = <0x03>;
		#address-cells = <0x00>;
		reg = <0x00 0xffb71000 0x00 0x1000 0x00 0xffb72000 0x00 0x2000 0x00 0xffb74000 0x00 0x2000 0x00 0xffb76000 0x00 0x2000>;
		interrupts = <0x01 0x09 0xff04>;
		phandle = <0x01>;
	};

	pinctrl {
		compatible = "rockchip,rk3368-pinctrl";
		rockchip,grf = <0x25>;
		rockchip,pmu = <0x43>;
		#address-cells = <0x02>;
		#size-cells = <0x02>;
		ranges;
		phandle = <0x8c>;

		gpio@ff750000 {
			compatible = "rockchip,gpio-bank";
			reg = <0x00 0xff750000 0x00 0x100>;
			clocks = <0x0a 0x140>;
			interrupts = <0x00 0x51 0x04>;
			gpio-controller;
			#gpio-cells = <0x02>;
			interrupt-controller;
			#interrupt-cells = <0x02>;
			phandle = <0x49>;
		};

		gpio@ff780000 {
			compatible = "rockchip,gpio-bank";
			reg = <0x00 0xff780000 0x00 0x100>;
			clocks = <0x0a 0x141>;
			interrupts = <0x00 0x52 0x04>;
			gpio-controller;
			#gpio-cells = <0x02>;
			interrupt-controller;
			#interrupt-cells = <0x02>;
			phandle = <0x8d>;
		};

		gpio@ff790000 {
			compatible = "rockchip,gpio-bank";
			reg = <0x00 0xff790000 0x00 0x100>;
			clocks = <0x0a 0x142>;
			interrupts = <0x00 0x53 0x04>;
			gpio-controller;
			#gpio-cells = <0x02>;
			interrupt-controller;
			#interrupt-cells = <0x02>;
			phandle = <0x4d>;
		};

		gpio@ff7a0000 {
			compatible = "rockchip,gpio-bank";
			reg = <0x00 0xff7a0000 0x00 0x100>;
			clocks = <0x0a 0x143>;
			interrupts = <0x00 0x54 0x04>;
			gpio-controller;
			#gpio-cells = <0x02>;
			interrupt-controller;
			#interrupt-cells = <0x02>;
			phandle = <0x27>;
		};

		pcfg-pull-up {
			bias-pull-up;
			phandle = <0x46>;
		};

		pcfg-pull-down {
			bias-pull-down;
			phandle = <0x8e>;
		};

		pcfg-pull-none {
			bias-disable;
			phandle = <0x47>;
		};

		pcfg-pull-none-12ma {
			bias-disable;
			drive-strength = <0x0c>;
			phandle = <0x48>;
		};

		emmc {

			emmc-clk {
				rockchip,pins = <0x02 0x04 0x02 0x44>;
				phandle = <0x0c>;
			};

			emmc-cmd {
				rockchip,pins = <0x01 0x1a 0x02 0x45>;
				phandle = <0x0d>;
			};

			emmc-pwr {
				rockchip,pins = <0x01 0x1b 0x02 0x46>;
				phandle = <0x8f>;
			};

			emmc-bus1 {
				rockchip,pins = <0x01 0x12 0x02 0x46>;
				phandle = <0x90>;
			};

			emmc-bus4 {
				rockchip,pins = <0x01 0x12 0x02 0x46 0x01 0x13 0x02 0x46 0x01 0x14 0x02 0x46 0x01 0x15 0x02 0x46>;
				phandle = <0x91>;
			};

			emmc-bus8 {
				rockchip,pins = <0x01 0x12 0x02 0x45 0x01 0x13 0x02 0x45 0x01 0x14 0x02 0x45 0x01 0x15 0x02 0x45 0x01 0x16 0x02 0x45 0x01 0x17 0x02 0x45 0x01 0x18 0x02 0x45 0x01 0x19 0x02 0x45>;
				phandle = <0x0e>;
			};

			emmc-reset {
				rockchip,pins = <0x02 0x03 0x00 0x47>;
				phandle = <0x4c>;
			};
		};

		gmac {

			rgmii-pins {
				rockchip,pins = <0x03 0x16 0x01 0x47 0x03 0x18 0x01 0x47 0x03 0x13 0x01 0x47 0x03 0x08 0x01 0x48 0x03 0x09 0x01 0x48 0x03 0x0a 0x01 0x48 0x03 0x0e 0x01 0x48 0x03 0x1c 0x01 0x48 0x03 0x0d 0x01 0x48 0x03 0x0f 0x01 0x47 0x03 0x10 0x01 0x47 0x03 0x11 0x01 0x47 0x03 0x12 0x01 0x47 0x03 0x19 0x01 0x47 0x03 0x14 0x01 0x47>;
				phandle = <0x92>;
			};

			rmii-pins {
				rockchip,pins = <0x03 0x16 0x01 0x47 0x03 0x18 0x01 0x47 0x03 0x13 0x01 0x47 0x03 0x08 0x01 0x48 0x03 0x09 0x01 0x48 0x03 0x0d 0x01 0x48 0x03 0x0f 0x01 0x47 0x03 0x10 0x01 0x47 0x03 0x14 0x01 0x47 0x03 0x15 0x01 0x47>;
				phandle = <0x28>;
			};
		};

		i2c0 {

			i2c0-xfer {
				rockchip,pins = <0x00 0x06 0x01 0x47 0x00 0x07 0x01 0x47>;
				phandle = <0x29>;
			};
		};

		i2c1 {

			i2c1-xfer {
				rockchip,pins = <0x02 0x15 0x01 0x47 0x02 0x16 0x01 0x47>;
				phandle = <0x2d>;
			};
		};

		i2c2 {

			i2c2-xfer {
				rockchip,pins = <0x00 0x09 0x02 0x47 0x03 0x1f 0x02 0x47>;
				phandle = <0x1b>;
			};
		};

		i2c3 {

			i2c3-xfer {
				rockchip,pins = <0x01 0x10 0x01 0x47 0x01 0x11 0x01 0x47>;
				phandle = <0x1c>;
			};
		};

		i2c4 {

			i2c4-xfer {
				rockchip,pins = <0x03 0x18 0x02 0x47 0x03 0x19 0x02 0x47>;
				phandle = <0x1d>;
			};
		};

		i2c5 {

			i2c5-xfer {
				rockchip,pins = <0x03 0x1a 0x02 0x47 0x03 0x1b 0x02 0x47>;
				phandle = <0x1e>;
			};
		};

		i2s {

			i2s-8ch-bus {
				rockchip,pins = <0x02 0x0c 0x01 0x47 0x02 0x0d 0x01 0x47 0x02 0x0e 0x01 0x47 0x02 0x0f 0x01 0x47 0x02 0x10 0x01 0x47 0x02 0x11 0x01 0x47 0x02 0x12 0x01 0x47 0x02 0x13 0x01 0x47 0x02 0x14 0x01 0x47>;
				phandle = <0x41>;
			};
		};

		pwm0 {

			pwm0-pin {
				rockchip,pins = <0x03 0x08 0x02 0x47>;
				phandle = <0x2e>;
			};
		};

		pwm1 {

			pwm1-pin {
				rockchip,pins = <0x00 0x08 0x02 0x47>;
				phandle = <0x2f>;
			};
		};

		pwm3 {

			pwm3-pin {
				rockchip,pins = <0x03 0x1d 0x03 0x47>;
				phandle = <0x30>;
			};
		};

		sdio0 {

			sdio0-bus1 {
				rockchip,pins = <0x02 0x1c 0x01 0x46>;
				phandle = <0x93>;
			};

			sdio0-bus4 {
				rockchip,pins = <0x02 0x1c 0x01 0x46 0x02 0x1d 0x01 0x46 0x02 0x1e 0x01 0x46 0x02 0x1f 0x01 0x46>;
				phandle = <0x94>;
			};

			sdio0-cmd {
				rockchip,pins = <0x03 0x00 0x01 0x46>;
				phandle = <0x95>;
			};

			sdio0-clk {
				rockchip,pins = <0x03 0x01 0x01 0x47>;
				phandle = <0x96>;
			};

			sdio0-cd {
				rockchip,pins = <0x03 0x02 0x01 0x46>;
				phandle = <0x97>;
			};

			sdio0-wp {
				rockchip,pins = <0x03 0x03 0x01 0x46>;
				phandle = <0x98>;
			};

			sdio0-pwr {
				rockchip,pins = <0x03 0x04 0x01 0x46>;
				phandle = <0x99>;
			};

			sdio0-bkpwr {
				rockchip,pins = <0x03 0x05 0x01 0x46>;
				phandle = <0x9a>;
			};

			sdio0-int {
				rockchip,pins = <0x03 0x06 0x01 0x46>;
				phandle = <0x9b>;
			};
		};

		sdmmc {

			sdmmc-clk {
				rockchip,pins = <0x02 0x09 0x01 0x47>;
				phandle = <0x9c>;
			};

			sdmmc-cmd {
				rockchip,pins = <0x02 0x0a 0x01 0x46>;
				phandle = <0x9d>;
			};

			sdmmc-cd {
				rockchip,pins = <0x02 0x0b 0x01 0x46>;
				phandle = <0x9e>;
			};

			sdmmc-bus1 {
				rockchip,pins = <0x02 0x05 0x01 0x46>;
				phandle = <0x9f>;
			};

			sdmmc-bus4 {
				rockchip,pins = <0x02 0x05 0x01 0x46 0x02 0x06 0x01 0x46 0x02 0x07 0x01 0x46 0x02 0x08 0x01 0x46>;
				phandle = <0xa0>;
			};
		};

		spdif {

			spdif-tx {
				rockchip,pins = <0x02 0x17 0x01 0x47>;
				phandle = <0x40>;
			};
		};

		spi0 {

			spi0-clk {
				rockchip,pins = <0x01 0x1d 0x02 0x46>;
				phandle = <0x0f>;
			};

			spi0-cs0 {
				rockchip,pins = <0x01 0x18 0x03 0x46>;
				phandle = <0x12>;
			};

			spi0-cs1 {
				rockchip,pins = <0x01 0x19 0x03 0x46>;
				phandle = <0xa1>;
			};

			spi0-tx {
				rockchip,pins = <0x01 0x17 0x03 0x46>;
				phandle = <0x10>;
			};

			spi0-rx {
				rockchip,pins = <0x01 0x16 0x03 0x46>;
				phandle = <0x11>;
			};
		};

		spi1 {

			spi1-clk {
				rockchip,pins = <0x01 0x0e 0x02 0x46>;
				phandle = <0x13>;
			};

			spi1-cs0 {
				rockchip,pins = <0x01 0x0f 0x02 0x46>;
				phandle = <0x16>;
			};

			spi1-cs1 {
				rockchip,pins = <0x03 0x1c 0x02 0x46>;
				phandle = <0xa2>;
			};

			spi1-rx {
				rockchip,pins = <0x01 0x10 0x02 0x46>;
				phandle = <0x15>;
			};

			spi1-tx {
				rockchip,pins = <0x01 0x11 0x02 0x46>;
				phandle = <0x14>;
			};
		};

		spi2 {

			spi2-clk {
				rockchip,pins = <0x00 0x0c 0x02 0x46>;
				phandle = <0x17>;
			};

			spi2-cs0 {
				rockchip,pins = <0x00 0x0d 0x02 0x46>;
				phandle = <0x1a>;
			};

			spi2-rx {
				rockchip,pins = <0x00 0x0a 0x02 0x46>;
				phandle = <0x19>;
			};

			spi2-tx {
				rockchip,pins = <0x00 0x0b 0x02 0x46>;
				phandle = <0x18>;
			};
		};

		tsadc {

			otp-pin {
				rockchip,pins = <0x00 0x03 0x00 0x47>;
				phandle = <0x23>;
			};

			otp-out {
				rockchip,pins = <0x00 0x03 0x01 0x47>;
				phandle = <0x24>;
			};
		};

		uart0 {

			uart0-xfer {
				rockchip,pins = <0x02 0x18 0x01 0x46 0x02 0x19 0x01 0x47>;
				phandle = <0xa3>;
			};

			uart0-cts {
				rockchip,pins = <0x02 0x1a 0x01 0x47>;
				phandle = <0xa4>;
			};

			uart0-rts {
				rockchip,pins = <0x02 0x1b 0x01 0x47>;
				phandle = <0xa5>;
			};
		};

		uart1 {

			uart1-xfer {
				rockchip,pins = <0x00 0x14 0x03 0x46 0x00 0x15 0x03 0x47>;
				phandle = <0xa6>;
			};

			uart1-cts {
				rockchip,pins = <0x00 0x16 0x03 0x47>;
				phandle = <0xa7>;
			};

			uart1-rts {
				rockchip,pins = <0x00 0x17 0x03 0x47>;
				phandle = <0xa8>;
			};
		};

		uart2 {

			uart2-xfer {
				rockchip,pins = <0x02 0x06 0x02 0x46 0x02 0x05 0x02 0x47>;
				phandle = <0x31>;
			};
		};

		uart3 {

			uart3-xfer {
				rockchip,pins = <0x03 0x1d 0x02 0x46 0x03 0x1e 0x03 0x47>;
				phandle = <0xa9>;
			};

			uart3-cts {
				rockchip,pins = <0x03 0x10 0x02 0x47>;
				phandle = <0xaa>;
			};

			uart3-rts {
				rockchip,pins = <0x03 0x11 0x02 0x47>;
				phandle = <0xab>;
			};
		};

		uart4 {

			uart4-xfer {
				rockchip,pins = <0x00 0x1b 0x03 0x46 0x00 0x1a 0x03 0x47>;
				phandle = <0xac>;
			};

			uart4-cts {
				rockchip,pins = <0x00 0x18 0x03 0x47>;
				phandle = <0xad>;
			};

			uart4-rts {
				rockchip,pins = <0x00 0x19 0x03 0x47>;
				phandle = <0xae>;
			};
		};

		pcfg-pull-none-drv-8ma {
			bias-disable;
			drive-strength = <0x08>;
			phandle = <0x44>;
		};

		pcfg-pull-up-drv-8ma {
			bias-pull-up;
			drive-strength = <0x08>;
			phandle = <0x45>;
		};

		backlight {

			bl-en {
				rockchip,pins = <0x00 0x14 0x00 0x47>;
				phandle = <0x4a>;
			};
		};

		keys {

			pwr-key {
				rockchip,pins = <0x00 0x02 0x00 0x46>;
				phandle = <0x4e>;
			};
		};

		pmic {

			pmic-int {
				rockchip,pins = <0x00 0x01 0x00 0x46>;
				phandle = <0xaf>;
			};
		};

		sdio {

			wifi-reg-on {
				rockchip,pins = <0x03 0x04 0x00 0x47>;
				phandle = <0xb0>;
			};

			bt-rst {
				rockchip,pins = <0x03 0x05 0x00 0x47>;
				phandle = <0xb1>;
			};
		};

		usb {

			host-vbus-drv {
				rockchip,pins = <0x00 0x04 0x00 0x47>;
				phandle = <0x4f>;
			};
		};
	};

	chosen {
		stdout-path = "serial2:115200n8";
	};

	memory {
		device_type = "memory";
		reg = <0x00 0x00 0x00 0x40000000>;
	};

	backlight {
		compatible = "pwm-backlight";
		brightness-levels = <0x00 0x01 0x02 0x03 0x04 0x05 0x06 0x07 0x08 0x09 0x0a 0x0b 0x0c 0x0d 0x0e 0x0f 0x10 0x11 0x12 0x13 0x14 0x15 0x16 0x17 0x18 0x19 0x1a 0x1b 0x1c 0x1d 0x1e 0x1f 0x20 0x21 0x22 0x23 0x24 0x25 0x26 0x27 0x28 0x29 0x2a 0x2b 0x2c 0x2d 0x2e 0x2f 0x30 0x31 0x32 0x33 0x34 0x35 0x36 0x37 0x38 0x39 0x3a 0x3b 0x3c 0x3d 0x3e 0x3f 0x40 0x41 0x42 0x43 0x44 0x45 0x46 0x47 0x48 0x49 0x4a 0x4b 0x4c 0x4d 0x4e 0x4f 0x50 0x51 0x52 0x53 0x54 0x55 0x56 0x57 0x58 0x59 0x5a 0x5b 0x5c 0x5d 0x5e 0x5f 0x60 0x61 0x62 0x63 0x64 0x65 0x66 0x67 0x68 0x69 0x6a 0x6b 0x6c 0x6d 0x6e 0x6f 0x70 0x71 0x72 0x73 0x74 0x75 0x76 0x77 0x78 0x79 0x7a 0x7b 0x7c 0x7d 0x7e 0x7f 0x80 0x81 0x82 0x83 0x84 0x85 0x86 0x87 0x88 0x89 0x8a 0x8b 0x8c 0x8d 0x8e 0x8f 0x90 0x91 0x92 0x93 0x94 0x95 0x96 0x97 0x98 0x99 0x9a 0x9b 0x9c 0x9d 0x9e 0x9f 0xa0 0xa1 0xa2 0xa3 0xa4 0xa5 0xa6 0xa7 0xa8 0xa9 0xaa 0xab 0xac 0xad 0xae 0xaf 0xb0 0xb1 0xb2 0xb3 0xb4 0xb5 0xb6 0xb7 0xb8 0xb9 0xba 0xbb 0xbc 0xbd 0xbe 0xbf 0xc0 0xc1 0xc2 0xc3 0xc4 0xc5 0xc6 0xc7 0xc8 0xc9 0xca 0xcb 0xcc 0xcd 0xce 0xcf 0xd0 0xd1 0xd2 0xd3 0xd4 0xd5 0xd6 0xd7 0xd8 0xd9 0xda 0xdb 0xdc 0xdd 0xde 0xdf 0xe0 0xe1 0xe2 0xe3 0xe4 0xe5 0xe6 0xe7 0xe8 0xe9 0xea 0xeb 0xec 0xed 0xee 0xef 0xf0 0xf1 0xf2 0xf3 0xf4 0xf5 0xf6 0xf7 0xf8 0xf9 0xfa 0xfb 0xfc 0xfd 0xfe 0xff>;
		default-brightness-level = <0x80>;
		enable-gpios = <0x49 0x14 0x00>;
		pinctrl-names = "default";
		pinctrl-0 = <0x4a>;
		pwms = <0x4b 0x00 0xf4240 0x01>;
		pwm-delay-us = <0x2710>;
		phandle = <0xb2>;
	};

	emmc-pwrseq {
		compatible = "mmc-pwrseq-emmc";
		pinctrl-0 = <0x4c>;
		pinctrl-names = "default";
		reset-gpios = <0x4d 0x03 0x00>;
		phandle = <0x0b>;
	};

	gpio-keys {
		compatible = "gpio-keys";
		pinctrl-names = "default";
		pinctrl-0 = <0x4e>;
		phandle = <0xb3>;

		power {
			wakeup-source;
			gpios = <0x49 0x02 0x01>;
			label = "GPIO Power";
			linux,code = <0x74>;
		};
	};

	vcc-host-regulator {
		compatible = "regulator-fixed";
		enable-active-high;
		gpio = <0x49 0x04 0x00>;
		pinctrl-names = "default";
		pinctrl-0 = <0x4f>;
		regulator-name = "vcc_host";
		regulator-always-on;
		regulator-boot-on;
		vin-supply = <0x2a>;
		phandle = <0xb4>;
	};

	vcc-lan-regulator {
		compatible = "regulator-fixed";
		regulator-name = "vcc_lan";
		regulator-min-microvolt = <0x325aa0>;
		regulator-max-microvolt = <0x325aa0>;
		regulator-always-on;
		regulator-boot-on;
		vin-supply = <0x2b>;
		phandle = <0x26>;
	};

	vcc-sys-regulator {
		compatible = "regulator-fixed";
		regulator-name = "vcc_sys";
		regulator-min-microvolt = <0x4c4b40>;
		regulator-max-microvolt = <0x4c4b40>;
		regulator-always-on;
		regulator-boot-on;
		phandle = <0x2a>;
	};

	__symbols__ {
		cpu_l0 = "/cpus/cpu@0";
		cpu_l1 = "/cpus/cpu@1";
		cpu_l2 = "/cpus/cpu@2";
		cpu_l3 = "/cpus/cpu@3";
		cpu_b0 = "/cpus/cpu@100";
		cpu_b1 = "/cpus/cpu@101";
		cpu_b2 = "/cpus/cpu@102";
		cpu_b3 = "/cpus/cpu@103";
		xin24m = "/oscillator";
		sdmmc = "/mmc@ff0c0000";
		sdio0 = "/mmc@ff0d0000";
		emmc = "/mmc@ff0f0000";
		saradc = "/saradc@ff100000";
		spi0 = "/spi@ff110000";
		spi1 = "/spi@ff120000";
		spi2 = "/spi@ff130000";
		i2c2 = "/i2c@ff140000";
		i2c3 = "/i2c@ff150000";
		i2c4 = "/i2c@ff160000";
		i2c5 = "/i2c@ff170000";
		uart0 = "/serial@ff180000";
		uart1 = "/serial@ff190000";
		uart3 = "/serial@ff1b0000";
		uart4 = "/serial@ff1c0000";
		dmac_peri = "/dma-controller@ff250000";
		cpu_thermal = "/thermal-zones/cpu-thermal";
		cpu_alert0 = "/thermal-zones/cpu-thermal/trips/cpu_alert0";
		cpu_alert1 = "/thermal-zones/cpu-thermal/trips/cpu_alert1";
		cpu_crit = "/thermal-zones/cpu-thermal/trips/cpu_crit";
		gpu_thermal = "/thermal-zones/gpu-thermal";
		gpu_alert0 = "/thermal-zones/gpu-thermal/trips/gpu_alert0";
		gpu_crit = "/thermal-zones/gpu-thermal/trips/gpu_crit";
		tsadc = "/tsadc@ff280000";
		gmac = "/ethernet@ff290000";
		usb_host0_ehci = "/usb@ff500000";
		usb_otg = "/usb@ff580000";
		dmac_bus = "/dma-controller@ff600000";
		i2c0 = "/i2c@ff650000";
		vdd_cpu = "/i2c@ff650000/syr827@40";
		vdd_gpu = "/i2c@ff650000/syr828@41";
		act8846 = "/i2c@ff650000/act8846@5a";
		vcc_ddr = "/i2c@ff650000/act8846@5a/regulators/REG1";
		vcc_io = "/i2c@ff650000/act8846@5a/regulators/REG2";
		vdd_log = "/i2c@ff650000/act8846@5a/regulators/REG3";
		vcc_20 = "/i2c@ff650000/act8846@5a/regulators/REG4";
		vccio_sd = "/i2c@ff650000/act8846@5a/regulators/REG5";
		vdd10_lcd = "/i2c@ff650000/act8846@5a/regulators/REG6";
		vcca_codec = "/i2c@ff650000/act8846@5a/regulators/REG7";
		vcca_tp = "/i2c@ff650000/act8846@5a/regulators/REG8";
		vccio_pmu = "/i2c@ff650000/act8846@5a/regulators/REG9";
		vdd_10 = "/i2c@ff650000/act8846@5a/regulators/REG10";
		vcc_18 = "/i2c@ff650000/act8846@5a/regulators/REG11";
		vcc18_lcd = "/i2c@ff650000/act8846@5a/regulators/REG12";
		i2c1 = "/i2c@ff660000";
		pwm0 = "/pwm@ff680000";
		pwm1 = "/pwm@ff680010";
		pwm2 = "/pwm@ff680020";
		pwm3 = "/pwm@ff680030";
		uart2 = "/serial@ff690000";
		mbox = "/mbox@ff6b0000";
		pmu = "/power-management@ff730000";
		power = "/power-management@ff730000/power-controller";
		pmugrf = "/syscon@ff738000";
		pmu_io_domains = "/syscon@ff738000/io-domains";
		cru = "/clock-controller@ff760000";
		grf = "/syscon@ff770000";
		io_domains = "/syscon@ff770000/io-domains";
		wdt = "/watchdog@ff800000";
		timer0 = "/timer@ff810000";
		spdif = "/spdif@ff880000";
		i2s_2ch = "/i2s-2ch@ff890000";
		i2s_8ch = "/i2s-8ch@ff898000";
		iep_mmu = "/iommu@ff900800";
		isp_mmu = "/iommu@ff914000";
		vop_mmu = "/iommu@ff930300";
		hevc_mmu = "/iommu@ff9a0440";
		vpu_mmu = "/iommu@ff9a0800";
		qos_iep = "/qos@ffad0000";
		qos_isp_r0 = "/qos@ffad0080";
		qos_isp_r1 = "/qos@ffad0100";
		qos_isp_w0 = "/qos@ffad0180";
		qos_isp_w1 = "/qos@ffad0200";
		qos_vip = "/qos@ffad0280";
		qos_vop = "/qos@ffad0300";
		qos_rga_r = "/qos@ffad0380";
		qos_rga_w = "/qos@ffad0400";
		qos_hevc_r = "/qos@ffae0000";
		qos_vpu_r = "/qos@ffae0100";
		qos_vpu_w = "/qos@ffae0180";
		qos_gpu = "/qos@ffaf0000";
		efuse256 = "/efuse@ffb00000";
		cpu_leakage = "/efuse@ffb00000/cpu-leakage@17";
		temp_adjust = "/efuse@ffb00000/temp-adjust@1f";
		gic = "/interrupt-controller@ffb71000";
		pinctrl = "/pinctrl";
		gpio0 = "/pinctrl/gpio@ff750000";
		gpio1 = "/pinctrl/gpio@ff780000";
		gpio2 = "/pinctrl/gpio@ff790000";
		gpio3 = "/pinctrl/gpio@ff7a0000";
		pcfg_pull_up = "/pinctrl/pcfg-pull-up";
		pcfg_pull_down = "/pinctrl/pcfg-pull-down";
		pcfg_pull_none = "/pinctrl/pcfg-pull-none";
		pcfg_pull_none_12ma = "/pinctrl/pcfg-pull-none-12ma";
		emmc_clk = "/pinctrl/emmc/emmc-clk";
		emmc_cmd = "/pinctrl/emmc/emmc-cmd";
		emmc_pwr = "/pinctrl/emmc/emmc-pwr";
		emmc_bus1 = "/pinctrl/emmc/emmc-bus1";
		emmc_bus4 = "/pinctrl/emmc/emmc-bus4";
		emmc_bus8 = "/pinctrl/emmc/emmc-bus8";
		emmc_reset = "/pinctrl/emmc/emmc-reset";
		rgmii_pins = "/pinctrl/gmac/rgmii-pins";
		rmii_pins = "/pinctrl/gmac/rmii-pins";
		i2c0_xfer = "/pinctrl/i2c0/i2c0-xfer";
		i2c1_xfer = "/pinctrl/i2c1/i2c1-xfer";
		i2c2_xfer = "/pinctrl/i2c2/i2c2-xfer";
		i2c3_xfer = "/pinctrl/i2c3/i2c3-xfer";
		i2c4_xfer = "/pinctrl/i2c4/i2c4-xfer";
		i2c5_xfer = "/pinctrl/i2c5/i2c5-xfer";
		i2s_8ch_bus = "/pinctrl/i2s/i2s-8ch-bus";
		pwm0_pin = "/pinctrl/pwm0/pwm0-pin";
		pwm1_pin = "/pinctrl/pwm1/pwm1-pin";
		pwm3_pin = "/pinctrl/pwm3/pwm3-pin";
		sdio0_bus1 = "/pinctrl/sdio0/sdio0-bus1";
		sdio0_bus4 = "/pinctrl/sdio0/sdio0-bus4";
		sdio0_cmd = "/pinctrl/sdio0/sdio0-cmd";
		sdio0_clk = "/pinctrl/sdio0/sdio0-clk";
		sdio0_cd = "/pinctrl/sdio0/sdio0-cd";
		sdio0_wp = "/pinctrl/sdio0/sdio0-wp";
		sdio0_pwr = "/pinctrl/sdio0/sdio0-pwr";
		sdio0_bkpwr = "/pinctrl/sdio0/sdio0-bkpwr";
		sdio0_int = "/pinctrl/sdio0/sdio0-int";
		sdmmc_clk = "/pinctrl/sdmmc/sdmmc-clk";
		sdmmc_cmd = "/pinctrl/sdmmc/sdmmc-cmd";
		sdmmc_cd = "/pinctrl/sdmmc/sdmmc-cd";
		sdmmc_bus1 = "/pinctrl/sdmmc/sdmmc-bus1";
		sdmmc_bus4 = "/pinctrl/sdmmc/sdmmc-bus4";
		spdif_tx = "/pinctrl/spdif/spdif-tx";
		spi0_clk = "/pinctrl/spi0/spi0-clk";
		spi0_cs0 = "/pinctrl/spi0/spi0-cs0";
		spi0_cs1 = "/pinctrl/spi0/spi0-cs1";
		spi0_tx = "/pinctrl/spi0/spi0-tx";
		spi0_rx = "/pinctrl/spi0/spi0-rx";
		spi1_clk = "/pinctrl/spi1/spi1-clk";
		spi1_cs0 = "/pinctrl/spi1/spi1-cs0";
		spi1_cs1 = "/pinctrl/spi1/spi1-cs1";
		spi1_rx = "/pinctrl/spi1/spi1-rx";
		spi1_tx = "/pinctrl/spi1/spi1-tx";
		spi2_clk = "/pinctrl/spi2/spi2-clk";
		spi2_cs0 = "/pinctrl/spi2/spi2-cs0";
		spi2_rx = "/pinctrl/spi2/spi2-rx";
		spi2_tx = "/pinctrl/spi2/spi2-tx";
		otp_pin = "/pinctrl/tsadc/otp-pin";
		otp_out = "/pinctrl/tsadc/otp-out";
		uart0_xfer = "/pinctrl/uart0/uart0-xfer";
		uart0_cts = "/pinctrl/uart0/uart0-cts";
		uart0_rts = "/pinctrl/uart0/uart0-rts";
		uart1_xfer = "/pinctrl/uart1/uart1-xfer";
		uart1_cts = "/pinctrl/uart1/uart1-cts";
		uart1_rts = "/pinctrl/uart1/uart1-rts";
		uart2_xfer = "/pinctrl/uart2/uart2-xfer";
		uart3_xfer = "/pinctrl/uart3/uart3-xfer";
		uart3_cts = "/pinctrl/uart3/uart3-cts";
		uart3_rts = "/pinctrl/uart3/uart3-rts";
		uart4_xfer = "/pinctrl/uart4/uart4-xfer";
		uart4_cts = "/pinctrl/uart4/uart4-cts";
		uart4_rts = "/pinctrl/uart4/uart4-rts";
		pcfg_pull_none_drv_8ma = "/pinctrl/pcfg-pull-none-drv-8ma";
		pcfg_pull_up_drv_8ma = "/pinctrl/pcfg-pull-up-drv-8ma";
		bl_en = "/pinctrl/backlight/bl-en";
		pwr_key = "/pinctrl/keys/pwr-key";
		pmic_int = "/pinctrl/pmic/pmic-int";
		wifi_reg_on = "/pinctrl/sdio/wifi-reg-on";
		bt_rst = "/pinctrl/sdio/bt-rst";
		host_vbus_drv = "/pinctrl/usb/host-vbus-drv";
		backlight = "/backlight";
		emmc_pwrseq = "/emmc-pwrseq";
		keys = "/gpio-keys";
		vcc_host = "/vcc-host-regulator";
		vcc_lan = "/vcc-lan-regulator";
		vcc_sys = "/vcc-sys-regulator";
	};
};
